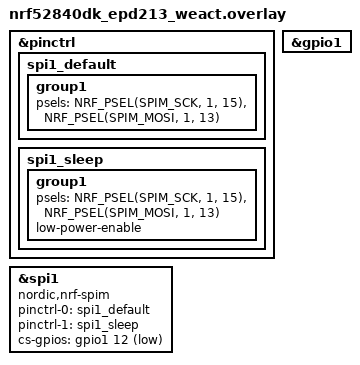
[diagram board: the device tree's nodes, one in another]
/*
 * nRF52840-DK + WeAct 2.13" E-Paper Display (122x250)
 * Pin Configuration for WeAct Studio standard pins
 *
 * SPI1 Pins:
 *   MOSI: P1.13
 *   SCK:  P1.15
 *   CS:   P1.12
 *
 * Control Pins:
 *   DC:   P1.10
 *   RES:  P1.11
 *   BUSY: P1.08
 */

&pinctrl {
	spi1_default: spi1_default {
		group1 {
			psels = <NRF_PSEL(SPIM_SCK, 1, 15)>,
				<NRF_PSEL(SPIM_MOSI, 1, 13)>;
		};
	};

	spi1_sleep: spi1_sleep {
		group1 {
			psels = <NRF_PSEL(SPIM_SCK, 1, 15)>,
				<NRF_PSEL(SPIM_MOSI, 1, 13)>;
			low-power-enable;
		};
	};
};

&spi1 {
	compatible = "nordic,nrf-spim";
	status = "okay";
	pinctrl-0 = <&spi1_default>;
	pinctrl-1 = <&spi1_sleep>;
	pinctrl-names = "default", "sleep";
	cs-gpios = <&gpio1 12 GPIO_ACTIVE_LOW>;
};

&gpio1 {
	status = "okay";
};
